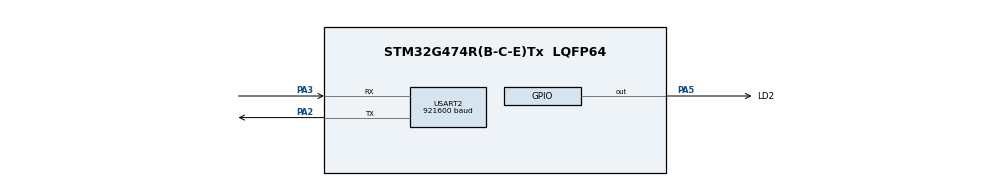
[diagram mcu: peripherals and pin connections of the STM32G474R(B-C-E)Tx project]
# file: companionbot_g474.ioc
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Dma.Request0=USART2_RX
Dma.Request1=USART2_TX
Dma.USART2_RX.0.Direction=DMA_PERIPH_TO_MEMORY
Dma.USART2_RX.0.EventEnable=DISABLE
Dma.USART2_RX.0.Instance=DMA1_Channel1
Dma.USART2_RX.0.MemDataAlignment=DMA_MDATAALIGN_BYTE
Dma.USART2_RX.0.MemInc=DMA_MINC_ENABLE
Dma.USART2_RX.0.Mode=DMA_CIRCULAR
Dma.USART2_RX.0.PeriphDataAlignment=DMA_PDATAALIGN_BYTE
Dma.USART2_RX.0.PeriphInc=DMA_PINC_DISABLE
Dma.USART2_RX.0.Polarity=HAL_DMAMUX_REQ_GEN_RISING
Dma.USART2_RX.0.Priority=DMA_PRIORITY_HIGH
Dma.USART2_RX.0.RequestNumber=1
Dma.USART2_RX.0.SignalID=NONE
Dma.USART2_RX.0.SyncEnable=DISABLE
Dma.USART2_RX.0.SyncPolarity=HAL_DMAMUX_SYNC_NO_EVENT
Dma.USART2_RX.0.SyncRequestNumber=1
Dma.USART2_RX.0.SyncSignalID=NONE
Dma.USART2_TX.1.Direction=DMA_MEMORY_TO_PERIPH
Dma.USART2_TX.1.EventEnable=DISABLE
Dma.USART2_TX.1.Instance=DMA1_Channel2
Dma.USART2_TX.1.MemDataAlignment=DMA_MDATAALIGN_BYTE
Dma.USART2_TX.1.MemInc=DMA_MINC_ENABLE
Dma.USART2_TX.1.Mode=DMA_NORMAL
Dma.USART2_TX.1.PeriphDataAlignment=DMA_PDATAALIGN_BYTE
Dma.USART2_TX.1.PeriphInc=DMA_PINC_DISABLE
Dma.USART2_TX.1.Polarity=HAL_DMAMUX_REQ_GEN_RISING
Dma.USART2_TX.1.Priority=DMA_PRIORITY_LOW
Dma.USART2_TX.1.RequestNumber=1
Dma.USART2_TX.1.SignalID=NONE
Dma.USART2_TX.1.SyncEnable=DISABLE
Dma.USART2_TX.1.SyncPolarity=HAL_DMAMUX_SYNC_NO_EVENT
Dma.USART2_TX.1.SyncRequestNumber=1
Dma.USART2_TX.1.SyncSignalID=NONE
IWDG.Prescaler=IWDG_PRESCALER_64
IWDG.Reload=124
Mcu.Family=STM32G4
Mcu.Name=STM32G474R(B-C-E)Tx
Mcu.Package=LQFP64
NVIC.DMA1_Channel1_IRQn=true\:2\:0\:false\:false\:true\:true\:true\:true
NVIC.DMA1_Channel2_IRQn=true\:2\:0\:false\:false\:true\:true\:true\:true
NVIC.PriorityGroup=NVIC_PRIORITYGROUP_4
NVIC.TIM6_DAC_IRQn=true\:1\:0\:false\:false\:true\:true\:true\:true
NVIC.USART2_IRQn=true\:2\:0\:false\:false\:true\:true\:true\:true
PA13.Mode=Serial_Wire
PA13.Signal=SYS_JTMS-SWDIO
PA14.Mode=Serial_Wire
PA14.Signal=SYS_JTCK-SWCLK
PA2.GPIO_PuPd=GPIO_PULLUP
PA2.Mode=Asynchronous
PA2.Signal=USART2_TX
PA3.GPIO_PuPd=GPIO_PULLUP
PA3.Mode=Asynchronous
PA3.Signal=USART2_RX
PA5.GPIO_Label=LD2
PA5.Signal=GPIO_Output
ProjectManager.HeapSize=0x0
ProjectManager.StackSize=0x2000
ProjectManager.TargetToolchain=MDK-ARM V5
RCC.AHBFreq_Value=170000000
RCC.APB1Freq_Value=170000000
RCC.APB1TimFreq_Value=170000000
RCC.APB2Freq_Value=170000000
RCC.APB2TimFreq_Value=170000000
RCC.CortexFreq_Value=170000000
RCC.EXTERNAL_CLOCK_VALUE=12288000
RCC.HCLKFreq_Value=170000000
RCC.HSE_VALUE=8000000
RCC.HSI48_VALUE=48000000
RCC.HSI_VALUE=16000000
RCC.LSE_VALUE=32768
RCC.LSIState=RCC_LSI_ON
RCC.PLLM=RCC_PLLM_DIV4
RCC.PLLN=85
RCC.PLLP=RCC_PLLP_DIV2
RCC.PLLQ=RCC_PLLQ_DIV2
RCC.PLLR=RCC_PLLR_DIV2
RCC.PLLSourceVirtual=RCC_PLLSOURCE_HSI
RCC.SYSCLKFreq_VALUE=170000000
RCC.SYSCLKSource=RCC_SYSCLKSOURCE_PLLCLK
RCC.USBFreq_Value=64000000
RCC.VCOOutputFreq_Value=340000000
TIM6.Period=1999
TIM6.Prescaler=169
USART2.BaudRate=921600
VP_IWDG_VS_IWDG.Mode=IWDG_Activate
VP_SYS_VS_DBSignals.Mode=DisableDeadBatterySignals
VP_TIM6_VS_ClockSourceINT.Mode=Enable_Timer
board=NUCLEO-G474RE

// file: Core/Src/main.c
/* Board configuration adapted from ST CubeG4 NUCLEO-G474RE HAL templates.
 * Peripheral drivers/startup/system remain unmodified external ST sources. */
#include "main.h"
/* USER CODE BEGIN Includes */
#include "app.h"
/* USER CODE END Includes */
UART_HandleTypeDef huart2;
DMA_HandleTypeDef hdma_usart2_rx, hdma_usart2_tx;
TIM_HandleTypeDef htim6;
IWDG_HandleTypeDef hiwdg;

static void SystemClock_Config(void) {
    RCC_OscInitTypeDef osc={0}; RCC_ClkInitTypeDef clk={0};
    if(HAL_PWREx_ControlVoltageScaling(PWR_REGULATOR_VOLTAGE_SCALE1_BOOST)!=HAL_OK) Error_Handler();
    osc.OscillatorType=RCC_OSCILLATORTYPE_HSI|RCC_OSCILLATORTYPE_LSI;
    osc.HSIState=RCC_HSI_ON; osc.HSICalibrationValue=RCC_HSICALIBRATION_DEFAULT; osc.LSIState=RCC_LSI_ON;
    osc.PLL.PLLState=RCC_PLL_ON; osc.PLL.PLLSource=RCC_PLLSOURCE_HSI;
    osc.PLL.PLLM=RCC_PLLM_DIV4; osc.PLL.PLLN=85;
    osc.PLL.PLLP=RCC_PLLP_DIV2; osc.PLL.PLLQ=RCC_PLLQ_DIV2; osc.PLL.PLLR=RCC_PLLR_DIV2;
    if(HAL_RCC_OscConfig(&osc)!=HAL_OK) Error_Handler();
    clk.ClockType=RCC_CLOCKTYPE_HCLK|RCC_CLOCKTYPE_SYSCLK|RCC_CLOCKTYPE_PCLK1|RCC_CLOCKTYPE_PCLK2;
    clk.SYSCLKSource=RCC_SYSCLKSOURCE_PLLCLK; clk.AHBCLKDivider=RCC_SYSCLK_DIV1;
    clk.APB1CLKDivider=RCC_HCLK_DIV1; clk.APB2CLKDivider=RCC_HCLK_DIV1;
    if(HAL_RCC_ClockConfig(&clk,FLASH_LATENCY_4)!=HAL_OK) Error_Handler();
}
static void MX_GPIO_Init(void) {
    GPIO_InitTypeDef gpio={0}; __HAL_RCC_GPIOA_CLK_ENABLE();
    HAL_GPIO_WritePin(GPIOA,GPIO_PIN_5,GPIO_PIN_RESET);
    gpio.Pin=GPIO_PIN_5; gpio.Mode=GPIO_MODE_OUTPUT_PP; gpio.Pull=GPIO_NOPULL;
    gpio.Speed=GPIO_SPEED_FREQ_LOW; HAL_GPIO_Init(GPIOA,&gpio);
}
static void MX_DMA_Init(void) {
    __HAL_RCC_DMAMUX1_CLK_ENABLE(); __HAL_RCC_DMA1_CLK_ENABLE();
    HAL_NVIC_SetPriority(DMA1_Channel1_IRQn,2,0); HAL_NVIC_EnableIRQ(DMA1_Channel1_IRQn);
    HAL_NVIC_SetPriority(DMA1_Channel2_IRQn,2,0); HAL_NVIC_EnableIRQ(DMA1_Channel2_IRQn);
}
static void MX_USART2_UART_Init(void) {
    huart2.Instance=USART2; huart2.Init.BaudRate=921600; huart2.Init.WordLength=UART_WORDLENGTH_8B;
    huart2.Init.StopBits=UART_STOPBITS_1; huart2.Init.Parity=UART_PARITY_NONE;
    huart2.Init.Mode=UART_MODE_TX_RX; huart2.Init.HwFlowCtl=UART_HWCONTROL_NONE;
    huart2.Init.OverSampling=UART_OVERSAMPLING_16; huart2.Init.OneBitSampling=UART_ONE_BIT_SAMPLE_DISABLE;
    huart2.Init.ClockPrescaler=UART_PRESCALER_DIV1; huart2.AdvancedInit.AdvFeatureInit=UART_ADVFEATURE_NO_INIT;
    if(HAL_UART_Init(&huart2)!=HAL_OK || HAL_UARTEx_DisableFifoMode(&huart2)!=HAL_OK) Error_Handler();
}
static void MX_TIM6_Init(void) {
    htim6.Instance=TIM6; htim6.Init.Prescaler=169; htim6.Init.CounterMode=TIM_COUNTERMODE_UP;
    htim6.Init.Period=1999; htim6.Init.AutoReloadPreload=TIM_AUTORELOAD_PRELOAD_DISABLE;
    if(HAL_TIM_Base_Init(&htim6)!=HAL_OK) Error_Handler();
}
static void MX_IWDG_Init(void) {
    hiwdg.Instance=IWDG; hiwdg.Init.Prescaler=IWDG_PRESCALER_64;
    hiwdg.Init.Window=IWDG_WINDOW_DISABLE; hiwdg.Init.Reload=124;
    if(HAL_IWDG_Init(&hiwdg)!=HAL_OK) Error_Handler();
}
int main(void) {
    HAL_Init(); SystemClock_Config(); MX_GPIO_Init(); MX_DMA_Init();
    MX_USART2_UART_Init(); MX_TIM6_Init(); MX_IWDG_Init();
    /* USER CODE BEGIN 2 */
    cb_app_init();
    /* USER CODE END 2 */
    while(1) {
        /* USER CODE BEGIN 3 */
        cb_app_poll();
    }
    /* USER CODE END 3 */
}
void Error_Handler(void) { __disable_irq(); for(;;) {} }
